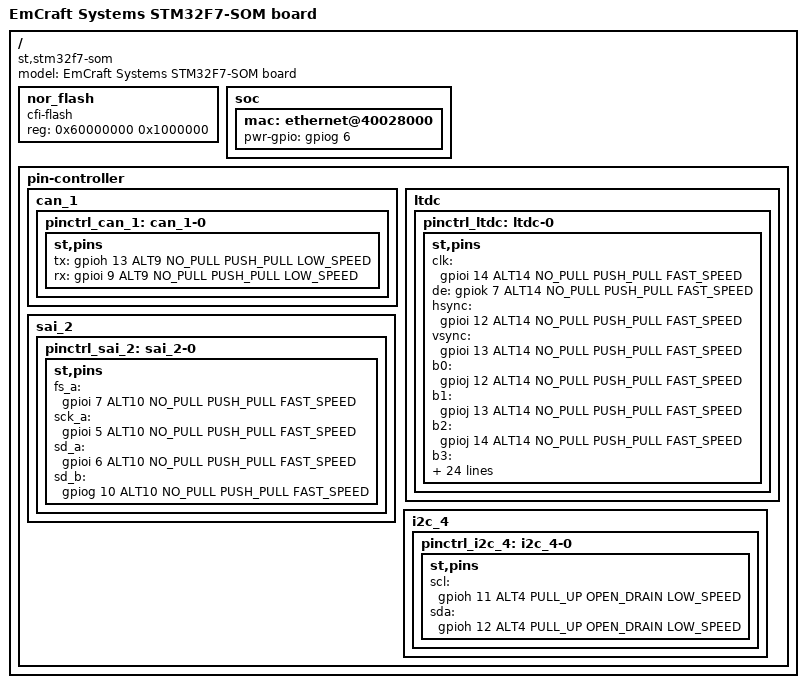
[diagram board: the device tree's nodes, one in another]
/*
 * Copyright 2016
 * Yuri Tikhonov, Emcraft Systems, <yur@emcraft.com>
 *
 * STM32F7-SOM module
 *
 * This program is free software; you can redistribute it and/or modify
 * it under the terms of the GNU General Public License version 2 as
 * publishhed by the Free Software Foundation.
 */

#include "stm32f7.dtsi"
#include "stm32-som.dtsi"
#include "dt-bindings/gpio/gpio.h"

/ {
	model = "EmCraft Systems STM32F7-SOM board";
	compatible = "st,stm32f7-som", "st,stm32f7";

	nor_flash {
		compatible = "cfi-flash";
		reg = <0x60000000 0x1000000>;
	};

	soc {
		mac: ethernet@40028000 {
			pwr-gpio = <&gpiog 6 GPIO_ACTIVE_HIGH>;
		};
	};

	pin-controller {
		can_1 {
			pinctrl_can_1: can_1-0 {
				st,pins {
					tx = <&gpioh 13 ALT9
						NO_PULL PUSH_PULL LOW_SPEED>;
					rx = <&gpioi 9 ALT9
						NO_PULL PUSH_PULL LOW_SPEED>;
				};
			};
		};

		ltdc {
			pinctrl_ltdc: ltdc-0 {
				st,pins {
					clk = <&gpioi 14 ALT14
						NO_PULL PUSH_PULL FAST_SPEED>;
					de = <&gpiok 7 ALT14
						NO_PULL PUSH_PULL FAST_SPEED>;
					hsync = <&gpioi 12 ALT14
						NO_PULL PUSH_PULL FAST_SPEED>;
					vsync = <&gpioi 13 ALT14
						NO_PULL PUSH_PULL FAST_SPEED>;
					b0 = <&gpioj 12 ALT14
						NO_PULL PUSH_PULL FAST_SPEED>;
					b1 = <&gpioj 13 ALT14
						NO_PULL PUSH_PULL FAST_SPEED>;
					b2 = <&gpioj 14 ALT14
						NO_PULL PUSH_PULL FAST_SPEED>;
					b3 = <&gpioj 15 ALT14
						NO_PULL PUSH_PULL FAST_SPEED>;
					b4 = <&gpiok 3 ALT14
						NO_PULL PUSH_PULL FAST_SPEED>;
					b5 = <&gpiok 4 ALT14
						NO_PULL PUSH_PULL FAST_SPEED>;
					b6 = <&gpiok 5 ALT14
						NO_PULL PUSH_PULL FAST_SPEED>;
					b7 = <&gpiok 6 ALT14
						NO_PULL PUSH_PULL FAST_SPEED>;
					g0 = <&gpioj 7 ALT14
						NO_PULL PUSH_PULL FAST_SPEED>;
					g1 = <&gpioj 8 ALT14
						NO_PULL PUSH_PULL FAST_SPEED>;
					g2 = <&gpioj 9 ALT14
						NO_PULL PUSH_PULL FAST_SPEED>;
					g3 = <&gpioj 10 ALT14
						NO_PULL PUSH_PULL FAST_SPEED>;
					g4 = <&gpioj 11 ALT14
						NO_PULL PUSH_PULL FAST_SPEED>;
					g5 = <&gpiok 0 ALT14
						NO_PULL PUSH_PULL FAST_SPEED>;
					g6 = <&gpiok 1 ALT14
						NO_PULL PUSH_PULL FAST_SPEED>;
					g7 = <&gpiok 2 ALT14
						NO_PULL PUSH_PULL FAST_SPEED>;
					r0 = <&gpioi 15 ALT14
						NO_PULL PUSH_PULL FAST_SPEED>;
					r1 = <&gpioj 0 ALT14
						NO_PULL PUSH_PULL FAST_SPEED>;
					r2 = <&gpioj 1 ALT14
						NO_PULL PUSH_PULL FAST_SPEED>;
					r3 = <&gpioj 2 ALT14
						NO_PULL PUSH_PULL FAST_SPEED>;
					r4 = <&gpioj 3 ALT14
						NO_PULL PUSH_PULL FAST_SPEED>;
					r5 = <&gpioj 4 ALT14
						NO_PULL PUSH_PULL FAST_SPEED>;
					r6 = <&gpioj 5 ALT14
						NO_PULL PUSH_PULL FAST_SPEED>;
					r7 = <&gpioj 6 ALT14
						NO_PULL PUSH_PULL FAST_SPEED>;
				};
			};
		};

		sai_2 {
			pinctrl_sai_2: sai_2-0 {
				st,pins {
					fs_a = <&gpioi 7 ALT10
						NO_PULL PUSH_PULL FAST_SPEED>;
					sck_a = <&gpioi 5 ALT10
						 NO_PULL PUSH_PULL FAST_SPEED>;
					sd_a = <&gpioi 6 ALT10
						NO_PULL PUSH_PULL FAST_SPEED>;
					sd_b = <&gpiog 10 ALT10
						NO_PULL PUSH_PULL FAST_SPEED>;
				};
			};
		};

		i2c_4 {
			pinctrl_i2c_4: i2c_4-0 {
				st,pins {
					scl = <&gpioh 11 ALT4
						PULL_UP OPEN_DRAIN LOW_SPEED>;
					sda = <&gpioh 12 ALT4
						PULL_UP OPEN_DRAIN LOW_SPEED>;
				};
			};
		};
	};
};
